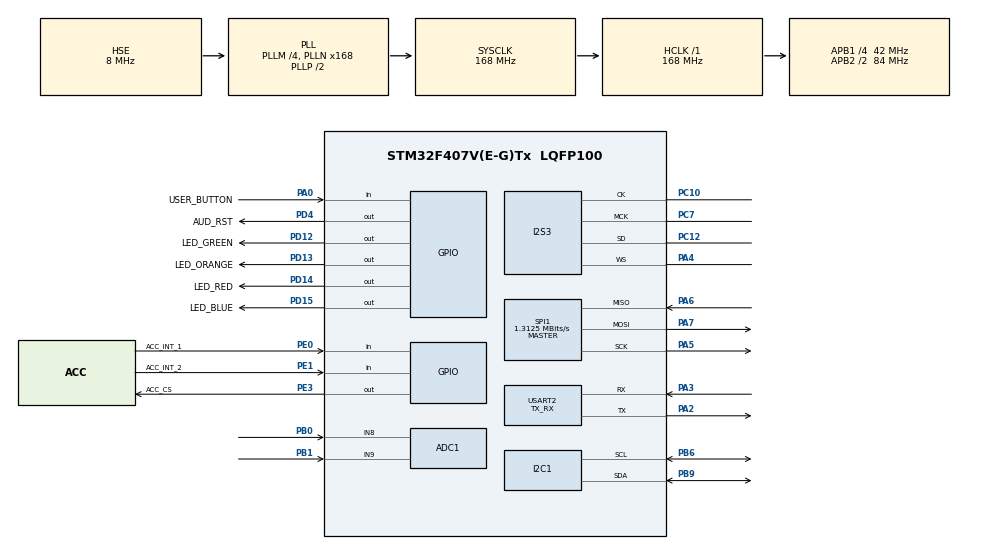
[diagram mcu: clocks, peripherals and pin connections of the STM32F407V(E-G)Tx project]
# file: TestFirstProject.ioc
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ADC1.Channel-0\#ChannelRegularConversion=ADC_CHANNEL_8
ADC1.Channel-1\#ChannelRegularConversion=ADC_CHANNEL_9
ADC1.NbrOfConversion=2
ADC1.NbrOfConversionFlag=1
ADC1.Rank-0\#ChannelRegularConversion=1
ADC1.Rank-1\#ChannelRegularConversion=2
ADC1.SamplingTime-0\#ChannelRegularConversion=ADC_SAMPLETIME_112CYCLES
ADC1.SamplingTime-1\#ChannelRegularConversion=ADC_SAMPLETIME_112CYCLES
ADC1.master=1
Dma.ADC1.0.Direction=DMA_PERIPH_TO_MEMORY
Dma.ADC1.0.FIFOMode=DMA_FIFOMODE_DISABLE
Dma.ADC1.0.Instance=DMA2_Stream0
Dma.ADC1.0.MemDataAlignment=DMA_MDATAALIGN_HALFWORD
Dma.ADC1.0.MemInc=DMA_MINC_ENABLE
Dma.ADC1.0.Mode=DMA_NORMAL
Dma.ADC1.0.PeriphDataAlignment=DMA_PDATAALIGN_HALFWORD
Dma.ADC1.0.PeriphInc=DMA_PINC_DISABLE
Dma.ADC1.0.Priority=DMA_PRIORITY_LOW
Dma.Request0=ADC1
I2S3.ErrorAudioFreq=-0.27 %
I2S3.FullDuplexMode=I2S_FULLDUPLEXMODE_DISABLE
I2S3.Instance=SPI$Index
I2S3.RealAudioFreq=7.978 KHz
I2S3.VirtualMode=I2S_MODE_MASTER
Mcu.Family=STM32F4
Mcu.Name=STM32F407V(E-G)Tx
Mcu.Package=LQFP100
NVIC.DMA2_Stream0_IRQn=true\:0\:0\:false\:false\:true\:false\:true
NVIC.PriorityGroup=NVIC_PRIORITYGROUP_4
NVIC.TIM8_TRG_COM_TIM14_IRQn=true\:0\:0\:false\:false\:true\:true\:true
NVIC.USART2_IRQn=true\:0\:0\:false\:false\:true\:true\:true
PA0-WKUP.GPIO_Label=USER_BUTTON
PA0-WKUP.Signal=GPIO_Input
PA13.Mode=Serial_Wire
PA13.Signal=SYS_JTMS-SWDIO
PA14.Mode=Serial_Wire
PA14.Signal=SYS_JTCK-SWCLK
PA2.Mode=Asynchronous
PA2.Signal=USART2_TX
PA3.Mode=Asynchronous
PA3.Signal=USART2_RX
PA4.Mode=Half_Duplex_Master
PA4.Signal=I2S3_WS
PA5.Mode=Full_Duplex_Master
PA5.Signal=SPI1_SCK
PA6.Mode=Full_Duplex_Master
PA6.Signal=SPI1_MISO
PA7.Mode=Full_Duplex_Master
PA7.Signal=SPI1_MOSI
PB0.Signal=ADCx_IN8
PB1.Signal=ADCx_IN9
PB10.Signal=I2S2_CK
PB6.Mode=I2C
PB6.Signal=I2C1_SCL
PB9.Mode=I2C
PB9.Signal=I2C1_SDA
PC10.Mode=Half_Duplex_Master
PC10.Signal=I2S3_CK
PC12.Mode=Half_Duplex_Master
PC12.Signal=I2S3_SD
PC3.Signal=I2S2_SD
PC7.Mode=Master_Clock_Activated
PC7.Signal=I2S3_MCK
PD12.GPIO_Label=LED_GREEN
PD12.Signal=GPIO_Output
PD13.GPIO_Label=LED_ORANGE
PD13.Signal=GPIO_Output
PD14.GPIO_Label=LED_RED
PD14.Signal=GPIO_Output
PD15.GPIO_Label=LED_BLUE
PD15.Signal=GPIO_Output
PD4.GPIO_Label=AUD_RST
PD4.PinState=GPIO_PIN_SET
PD4.Signal=GPIO_Output
PE0.GPIO_Label=ACC_INT_1
PE0.Signal=GPIO_Input
PE1.GPIO_Label=ACC_INT_2
PE1.Signal=GPIO_Input
PE3.GPIO_Label=ACC_CS
PE3.Signal=GPIO_Output
PH0-OSC_IN.Mode=HSE-External-Oscillator
PH0-OSC_IN.Signal=RCC_OSC_IN
PH1-OSC_OUT.Mode=HSE-External-Oscillator
PH1-OSC_OUT.Signal=RCC_OSC_OUT
ProjectManager.HeapSize=0x00
ProjectManager.StackSize=0x400
ProjectManager.TargetToolchain=STM32CubeIDE
RCC.48MHZClocksFreq_Value=84000000
RCC.AHBFreq_Value=168000000
RCC.APB1CLKDivider=RCC_HCLK_DIV4
RCC.APB1Freq_Value=42000000
RCC.APB1TimFreq_Value=84000000
RCC.APB2CLKDivider=RCC_HCLK_DIV2
RCC.APB2Freq_Value=84000000
RCC.APB2TimFreq_Value=168000000
RCC.CortexFreq_Value=168000000
RCC.HCLKFreq_Value=168000000
RCC.HSE_VALUE=8000000
RCC.HSI_VALUE=16000000
RCC.LSE_VALUE=32768
RCC.PLLM=4
RCC.PLLN=168
RCC.PLLSourceVirtual=RCC_PLLSOURCE_HSE
RCC.SYSCLKFreq_VALUE=168000000
RCC.SYSCLKSource=RCC_SYSCLKSOURCE_PLLCLK
RCC.VCOOutputFreq_Value=336000000
SH.ADCx_IN8.0=ADC1_IN8,IN8
SH.ADCx_IN9.0=ADC1_IN9,IN9
SPI1.BaudRatePrescaler=SPI_BAUDRATEPRESCALER_64
SPI1.CalculateBaudRate=1.3125 MBits/s
SPI1.Direction=SPI_DIRECTION_2LINES
SPI1.Mode=SPI_MODE_MASTER
SPI1.VirtualType=VM_MASTER
TIM14.AutoReloadPreload=TIM_AUTORELOAD_PRELOAD_ENABLE
TIM14.Period=999
TIM14.Prescaler=83
USART2.Mode=MODE_TX_RX
USART2.OverSampling=UART_OVERSAMPLING_8
USART2.VirtualMode=VM_ASYNC
VP_TIM14_VS_ClockSourceINT.Mode=Enable_Timer
board=custom

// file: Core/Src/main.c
/* USER CODE BEGIN Header */
/**
  ******************************************************************************
  * @file           : main.c
  * @brief          : Main program body
  ******************************************************************************
  * @attention
  *
  * <h2><center>&copy; Copyright (c) 2020 STMicroelectronics.
  * All rights reserved.</center></h2>
  *
  * This software component is licensed by ST under BSD 3-Clause license,
  * the "License"; You may not use this file except in compliance with the
  * License. You may obtain a copy of the License at:
  *                        opensource.org/licenses/BSD-3-Clause
  *
  ******************************************************************************
  */
/* USER CODE END Header */

#include "main.h"
#include "adc.h"
#include "dma.h"
#include "i2c.h"
#include "i2s.h"
#include "spi.h"
#include "tim.h"
#include "usart.h"
#include "gpio.h"

void SystemClock_Config(void);

int main(void)
{

  /* MCU Configuration--------------------------------------------------------*/

  /* Reset of all peripherals, Initializes the Flash interface and the Systick. */
  HAL_Init();

  /* Configure the system clock */
  SystemClock_Config();

  /* Initialize all configured peripherals */
  MX_GPIO_Init();
  MX_DMA_Init();
  MX_ADC1_Init();
  MX_I2C1_Init();
  MX_I2S3_Init();
  MX_SPI1_Init();
  MX_TIM14_Init();
  MX_USART2_UART_Init();

  /* Infinite loop */
  /* USER CODE BEGIN WHILE */
  while (1)
  {
      HAL_GPIO_WritePin ( LED_BLUE_GPIO_Port, LED_BLUE_Pin, GPIO_PIN_SET );
      HAL_GPIO_WritePin ( LED_ORANGE_GPIO_Port, LED_ORANGE_Pin, GPIO_PIN_RESET );
      HAL_Delay ( 250 );
      HAL_GPIO_WritePin ( LED_BLUE_GPIO_Port, LED_BLUE_Pin, GPIO_PIN_RESET );
      HAL_GPIO_WritePin ( LED_ORANGE_GPIO_Port, LED_ORANGE_Pin, GPIO_PIN_SET );
      HAL_Delay ( 250 );

      HAL_GPIO_TogglePin ( LED_RED_GPIO_Port, LED_RED_Pin );

    /* USER CODE END WHILE */

  }
}

void SystemClock_Config(void)
{
  RCC_OscInitTypeDef RCC_OscInitStruct = {0};
  RCC_ClkInitTypeDef RCC_ClkInitStruct = {0};
  RCC_PeriphCLKInitTypeDef PeriphClkInitStruct = {0};

  /** Configure the main internal regulator output voltage
  */
  __HAL_RCC_PWR_CLK_ENABLE();
  __HAL_PWR_VOLTAGESCALING_CONFIG(PWR_REGULATOR_VOLTAGE_SCALE1);
  /** Initializes the CPU, AHB and APB busses clocks
  */
  RCC_OscInitStruct.OscillatorType = RCC_OSCILLATORTYPE_HSE;
  RCC_OscInitStruct.HSEState = RCC_HSE_ON;
  RCC_OscInitStruct.PLL.PLLState = RCC_PLL_ON;
  RCC_OscInitStruct.PLL.PLLSource = RCC_PLLSOURCE_HSE;
  RCC_OscInitStruct.PLL.PLLM = 4;
  RCC_OscInitStruct.PLL.PLLN = 168;
  RCC_OscInitStruct.PLL.PLLP = RCC_PLLP_DIV2;
  RCC_OscInitStruct.PLL.PLLQ = 4;
  if (HAL_RCC_OscConfig(&RCC_OscInitStruct) != HAL_OK)
  {
    Error_Handler();
  }
  /** Initializes the CPU, AHB and APB busses clocks
  */
  RCC_ClkInitStruct.ClockType = RCC_CLOCKTYPE_HCLK|RCC_CLOCKTYPE_SYSCLK
                              |RCC_CLOCKTYPE_PCLK1|RCC_CLOCKTYPE_PCLK2;
  RCC_ClkInitStruct.SYSCLKSource = RCC_SYSCLKSOURCE_PLLCLK;
  RCC_ClkInitStruct.AHBCLKDivider = RCC_SYSCLK_DIV1;
  RCC_ClkInitStruct.APB1CLKDivider = RCC_HCLK_DIV4;
  RCC_ClkInitStruct.APB2CLKDivider = RCC_HCLK_DIV2;

  if (HAL_RCC_ClockConfig(&RCC_ClkInitStruct, FLASH_LATENCY_5) != HAL_OK)
  {
    Error_Handler();
  }
  PeriphClkInitStruct.PeriphClockSelection = RCC_PERIPHCLK_I2S;
  PeriphClkInitStruct.PLLI2S.PLLI2SN = 192;
  PeriphClkInitStruct.PLLI2S.PLLI2SR = 2;
  if (HAL_RCCEx_PeriphCLKConfig(&PeriphClkInitStruct) != HAL_OK)
  {
    Error_Handler();
  }
}

void Error_Handler(void)
{
}

/************************ (C) COPYRIGHT STMicroelectronics *****END OF FILE****/
